# FM33L0XXD register map
File version: 1.0
CPU: SC000 r1p0, little endian, no MPU, FPU, 8 interrupt priority bits
Registers are 32-bit, read-write, reset 0x0 unless marked. A register's access mark holds for its fields unless they carry their own. Offsets are from the block's base; [hi:lo] are bit positions; {n}, {i} and the like mark numbered series.

## AES — AES module information
Base 0x40013800
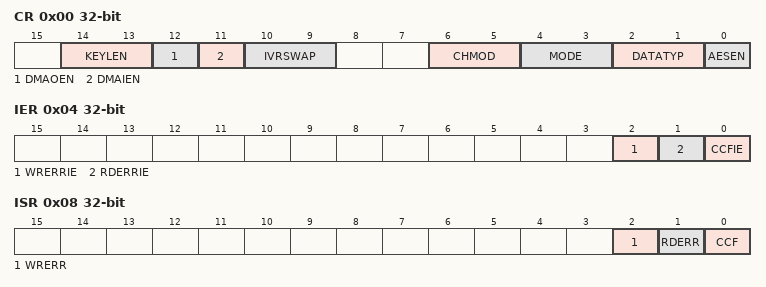
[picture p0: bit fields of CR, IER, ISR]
0x00 CR — AES_CR Register
  [14:13] KEYLEN — KEYLEN field description
  [12] DMAOEN — DMAOEN field description
  [11] DMAIEN — DMAIEN field description
  [10:9] IVRSWAP — IVRSWAP field description
  [6:5] CHMOD — CHMOD field description
  [4:3] MODE — MODE field description
  [2:1] DATATYP — DATATYP field description
  [0] AESEN — AESEN field description
0x04 IER — AES_IER Register
  [2] WRERRIE — WRERR_IE field description
  [1] RDERRIE — RDERR_IE field description
  [0] CCFIE — CCF_IE field description
0x08 ISR — AES_ISR Register
  [2] WRERR — WRERR field description
  [1] RDERR — RDERR field description
  [0] CCF — CCF field description
0x0C DIR — AES_DIR Register
  [31:0] AESDIN wo — AESDIN field description
0x10 DOR — AES_DOR Register
  [31:0] AESDOUT ro — AESDOUT field description
{0x14+4i} KEY{i} (i=0..3) — AES_KEY{i} Register
  [31:0] AESKEY{i} — AESKEY{i} field description
0x24 KEY4 — AES_KEY4 Register
  [31:0] AESKEY4 wo — AESKEY4 field description
{0x14+4i} KEY{i} (i=5..7) — AES_KEY{i} Register
  [31:0] AESKEY{i} — AESKEY{i} field description
{0x34+4i} IVR{i} (i=0..3) — AES_IVR{i} Register
  [31:0] AESIVR{i} — AESIVR{i} field description
{0x44+4i} H{i} (i=0..3) — AES_H{i} Register
  [31:0] AESH{i} — AESH{i} field description

## BSTIM1 — BSTIM1 module information
Base 0x40013000
Same registers: BSTIM2 0x40013044
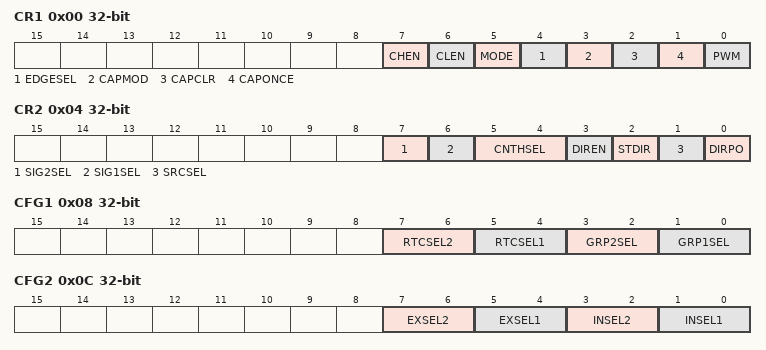
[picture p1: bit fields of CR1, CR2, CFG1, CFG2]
0x00 CR1
  [7] CHEN — CHEN field description
  [6] CLEN — CLEN field description
  [5] MODE — MODE field description
  [4] EDGESEL — EDGESEL field description
  [3] CAPMOD — CAPMOD field description
  [2] CAPCLR — CAPCLR field description
  [1] CAPONCE — CAPONCE field description
  [0] PWM — PWM field description
0x04 CR2
  [7] SIG2SEL — SIG2SEL field description
  [6] SIG1SEL — SIG1SEL field description
  [5:4] CNTHSEL — CNTHSEL field description
  [3] DIREN — DIREN field description
  [2] STDIR — STDIR field description
  [1] SRCSEL — SRCSEL field description
  [0] DIRPO — DIRPO field description
0x08 CFG1
  [7:6] RTCSEL2 — RTCSEL2 field description
  [5:4] RTCSEL1 — RTCSEL1 field description
  [3:2] GRP2SEL — GRP2SEL field description
  [1:0] GRP1SEL — GRP1SEL field description
0x0C CFG2
  [7:6] EXSEL2 — EXSEL2 field description
  [5:4] EXSEL1 — EXSEL1 field description
  [3:2] INSEL2 — INSEL2 field description
  [1:0] INSEL1 — INSEL1 field description
0x10 PRES
  [7:0] PRESCALE — PRESCALE field description
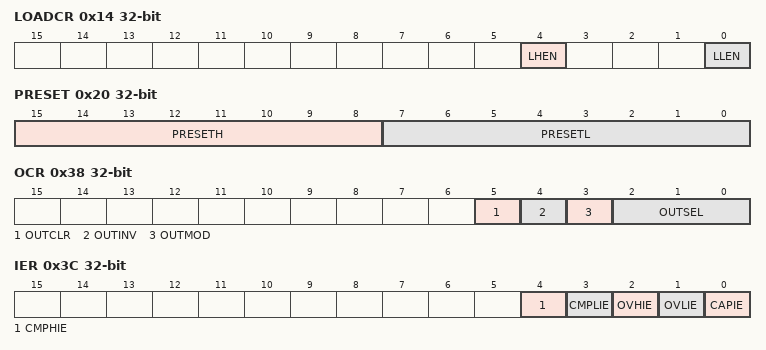
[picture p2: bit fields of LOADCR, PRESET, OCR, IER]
0x14 LOADCR
  [4] LHEN wo — LHEN field description
  [0] LLEN wo — LLEN field description
0x18 CNTL
  [7:0] CNTL ro — CNTL field description
0x1C CNTH
  [7:0] CNTH ro — CNTH field description
0x20 PRESET
  [15:8] PRESETH — PRESETH field description
  [7:0] PRESETL — PRESETL field description
0x24 LOADL
  [7:0] LOADL wo — LOADL field description
0x28 LOADH
  [7:0] LOADH wo — LOADH field description
0x2C CMPL
  [7:0] CMPL ro — CMPL field description
0x30 CMPH
  [7:0] CMPH ro — CMPH field description
0x34 OUTCNT
  [11:0] OUTCNT — OUTCNT field description
0x38 OCR
  [5] OUTCLR ro — OUTCLR field description
  [4] OUTINV — OUTINV field description
  [3] OUTMOD — OUTMOD field description
  [2:0] OUTSEL — OUTSEL field description
0x3C IER
  [4] CMPHIE — CMPHIE field description
  [3] CMPLIE — CMPLIE field description
  [2] OVHIE — OVHIE field description
  [1] OVLIE — OVLIE field description
  [0] CAPIE — CAPIE field description
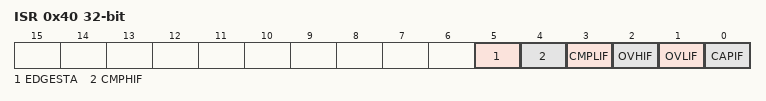
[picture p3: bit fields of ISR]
0x40 ISR
  [5] EDGESTA ro — EDGESTA field description
  [4] CMPHIF — CMPHIF field description
  [3] CMPLIF — CMPLIF field description
  [2] OVHIF — OVHIF field description
  [1] OVLIF — OVLIF field description
  [0] CAPIF — CAPIF field description

## COMP1 — COMP1 module information
Base 0x40012840
Same registers: COMP2 0x40012844
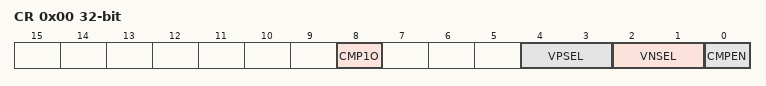
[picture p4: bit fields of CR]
0x00 CR
  [8] CMP1O ro — CMP1O field description
  [4:3] VPSEL — V1PSEL field description
  [2:1] VNSEL — V1NSEL field description
  [0] CMPEN — CMP1EN field description
